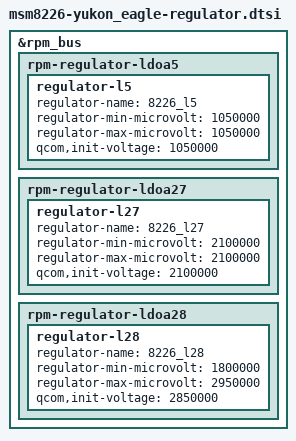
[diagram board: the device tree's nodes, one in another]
/* Copyright (c) 2012-2014, The Linux Foundation. All rights reserved.
 *
 * This program is free software; you can redistribute it and/or modify
 * it under the terms of the GNU General Public License version 2 and
 * only version 2 as published by the Free Software Foundation.
 *
 * This program is distributed in the hope that it will be useful,
 * but WITHOUT ANY WARRANTY; without even the implied warranty of
 * MERCHANTABILITY or FITNESS FOR A PARTICULAR PURPOSE.  See the
 * GNU General Public License for more details.
 */

&rpm_bus {
	rpm-regulator-ldoa5 {
		regulator-l5 {
			regulator-name = "8226_l5";
			regulator-min-microvolt = <1050000>;
			regulator-max-microvolt = <1050000>;
			qcom,init-voltage = <1050000>;
			status = "okay";
			};
		};
	rpm-regulator-ldoa27 {
		regulator-l27 {
			regulator-name = "8226_l27";
			regulator-min-microvolt = <2100000>;
			regulator-max-microvolt = <2100000>;
			qcom,init-voltage = <2100000>;
			status = "okay";
			};
		};
	rpm-regulator-ldoa28 {
		regulator-l28 {
			regulator-name = "8226_l28";
			regulator-min-microvolt = <1800000>;
			regulator-max-microvolt = <2950000>;
			qcom,init-voltage = <2850000>;
			status = "okay";
		};
	};
};
